# TLSR826X register map
File version: 0.1
Registers are 8-bit, access not given, no defined reset value unless marked. A register's access mark holds for its fields unless they carry their own. Offsets are from the block's base; [hi:lo] are bit positions.

## SYS — Auto-generated from section 'sys'
Base 0x00800060
0x00 RST0 32-bit — Auto-generated from rst0; aliases: RST0_16, RST_CLK0
  [31] FLD_CLK_ZB_EN, [30] FLD_CLK_ADC_EN, [29] FLD_CLK_MAC_EN, [28] FLD_CLK_MCU_EN, [27] FLD_CLK_USB_PHY_EN, [26] FLD_CLK_USB_EN, [25] FLD_CLK_I2C_EN, [24] FLD_CLK_SPI_EN, [23] FLD_RST_RSV, [22] FLD_RST_SOFT_MCIC, [21] FLD_RST_MCIC, [20] FLD_RST_SOFT_MCU, [19] FLD_RST_ADC, [18] FLD_RST_DFIFO, [17] FLD_RST_AUD, [16] FLD_RST_SBC, [15] FLD_RST_SWR_S, [14] FLD_RST_SWR_M, [13] FLD_RST_AES, [12] FLD_RST_PWM, [11] FLD_RST_UART, [10] FLD_RST_DMA, [9] FLD_RST_ALGM, [8] FLD_RST_GPIO, [7] FLD_RST_BB, [7] FLD_RST_ZB, [6] FLD_RST_AIF, [5] FLD_RST_MAC, [4] FLD_RST_MCU, [3] FLD_RST_USB_PHY, [2] FLD_RST_USB, [1] FLD_RST_I2C, [0] FLD_RST_SPI
0x01 RST1 — Auto-generated from rst1
0x02 RST2 — Auto-generated from rst2
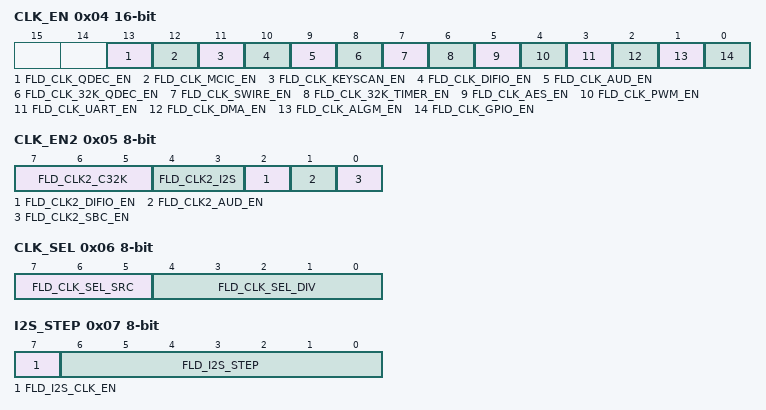
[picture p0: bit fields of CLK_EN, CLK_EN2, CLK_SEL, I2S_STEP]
0x04 CLK_EN 16-bit — Auto-generated from clk_en; aliases: CLK_EN1
  [13] FLD_CLK_QDEC_EN, [12] FLD_CLK_MCIC_EN, [11] FLD_CLK_KEYSCAN_EN, [10] FLD_CLK_DIFIO_EN, [9] FLD_CLK_AUD_EN, [8] FLD_CLK_32K_QDEC_EN, [7] FLD_CLK_SWIRE_EN, [6] FLD_CLK_32K_TIMER_EN, [5] FLD_CLK_AES_EN, [4] FLD_CLK_PWM_EN, [3] FLD_CLK_UART_EN, [2] FLD_CLK_DMA_EN, [1] FLD_CLK_ALGM_EN, [0] FLD_CLK_GPIO_EN
0x05 CLK_EN2 — Auto-generated from clk_en2
  [7:5] FLD_CLK2_C32K, [4:3] FLD_CLK2_I2S, [2] FLD_CLK2_DIFIO_EN, [1] FLD_CLK2_AUD_EN, [0] FLD_CLK2_SBC_EN
0x06 CLK_SEL — Auto-generated from clk_sel
  [7:5] FLD_CLK_SEL_SRC, [4:0] FLD_CLK_SEL_DIV
0x07 I2S_STEP — Auto-generated from i2s_step
  [7] FLD_I2S_CLK_EN, [6:0] FLD_I2S_STEP
0x08 I2S_MOD — Auto-generated from i2s_mod
0x09 ADC_STEP_L — Auto-generated from adc_step_l
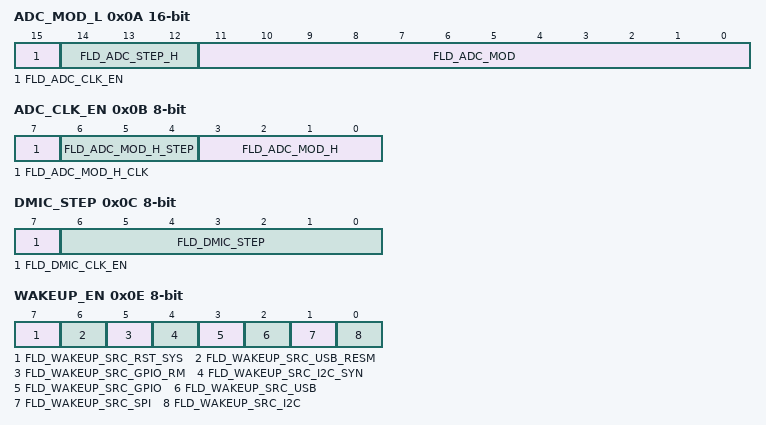
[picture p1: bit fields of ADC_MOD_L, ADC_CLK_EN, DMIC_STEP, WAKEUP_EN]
0x0A ADC_MOD_L 16-bit — Auto-generated from adc_mod_l; aliases: ADC_MOD
  [15] FLD_ADC_CLK_EN, [14:12] FLD_ADC_STEP_H, [11:0] FLD_ADC_MOD
0x0B ADC_CLK_EN — Auto-generated from adc_clk_en; aliases: ADC_MOD_H
  [7] FLD_ADC_MOD_H_CLK, [6:4] FLD_ADC_MOD_H_STEP, [3:0] FLD_ADC_MOD_H
0x0C DMIC_STEP — Auto-generated from dmic_step
  [7] FLD_DMIC_CLK_EN, [6:0] FLD_DMIC_STEP
0x0D DMIC_MOD — Auto-generated from dmic_mod
0x0E WAKEUP_EN — Auto-generated from wakeup_en
  [7] FLD_WAKEUP_SRC_RST_SYS, [6] FLD_WAKEUP_SRC_USB_RESM, [5] FLD_WAKEUP_SRC_GPIO_RM, [4] FLD_WAKEUP_SRC_I2C_SYN, [3] FLD_WAKEUP_SRC_GPIO, [2] FLD_WAKEUP_SRC_USB, [1] FLD_WAKEUP_SRC_SPI, [0] FLD_WAKEUP_SRC_I2C
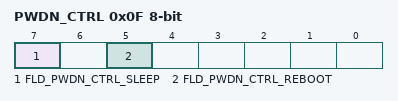
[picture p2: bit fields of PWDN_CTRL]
0x0F PWDN_CTRL — Auto-generated from pwdn_ctrl
  [7] FLD_PWDN_CTRL_SLEEP, [5] FLD_PWDN_CTRL_REBOOT
0x10 FHS_SEL — Auto-generated from fhs_sel
  [1:0] FLD_FHS_SELECT
0x11 DCDC_CLK — Auto-generated from dcdc_clk

## DEV_ID — Auto-generated from section 'dev_id'
Base 0x00800074
0x00 ID_WR_EN — Auto-generated from id_wr_en
0x04 MCU_WAKEUP_MASK 32-bit — Auto-generated from mcu_wakeup_mask
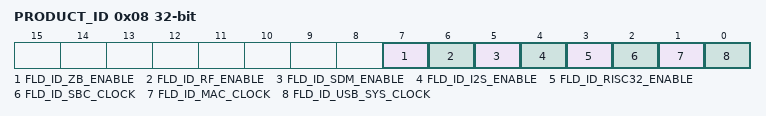
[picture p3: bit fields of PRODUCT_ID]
0x08 PRODUCT_ID 32-bit — Auto-generated from product_id; aliases: FUNC_ID
  [7] FLD_ID_ZB_ENABLE, [6] FLD_ID_RF_ENABLE, [5] FLD_ID_SDM_ENABLE, [4] FLD_ID_I2S_ENABLE, [3] FLD_ID_RISC32_ENABLE, [2] FLD_ID_SBC_CLOCK, [1] FLD_ID_MAC_CLOCK, [0] FLD_ID_USB_SYS_CLOCK
0x09 VER_ID — Auto-generated from ver_id
0x0A PROD_ID 16-bit — Auto-generated from prod_id

## MAC — Auto-generated from section 'mac'
Base 0x00800080
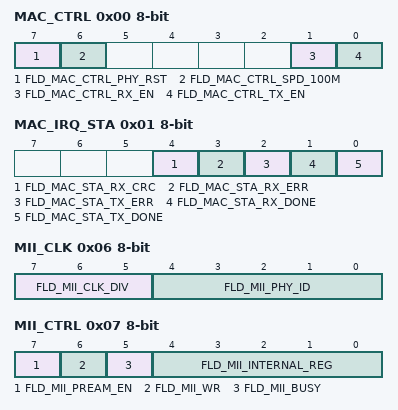
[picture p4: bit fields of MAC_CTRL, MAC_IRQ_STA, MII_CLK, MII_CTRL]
0x00 MAC_CTRL — Auto-generated from mac_ctrl
  [7] FLD_MAC_CTRL_PHY_RST, [6] FLD_MAC_CTRL_SPD_100M, [1] FLD_MAC_CTRL_RX_EN, [0] FLD_MAC_CTRL_TX_EN
0x01 MAC_IRQ_STA — Auto-generated from mac_irq_sta
  [4] FLD_MAC_STA_RX_CRC, [3] FLD_MAC_STA_RX_ERR, [2] FLD_MAC_STA_TX_ERR, [1] FLD_MAC_STA_RX_DONE, [0] FLD_MAC_STA_TX_DONE
0x02 MII_TX_DATA 16-bit — Auto-generated from mii_tx_data
0x04 MII_RX_DATA 16-bit — Auto-generated from mii_rx_data
0x06 MII_CLK — Auto-generated from mii_clk
  [7:5] FLD_MII_CLK_DIV, [4:0] FLD_MII_PHY_ID
0x07 MII_CTRL — Auto-generated from mii_ctrl
  [7] FLD_MII_PREAM_EN, [6] FLD_MII_WR, [5] FLD_MII_BUSY, [4:0] FLD_MII_INTERNAL_REG
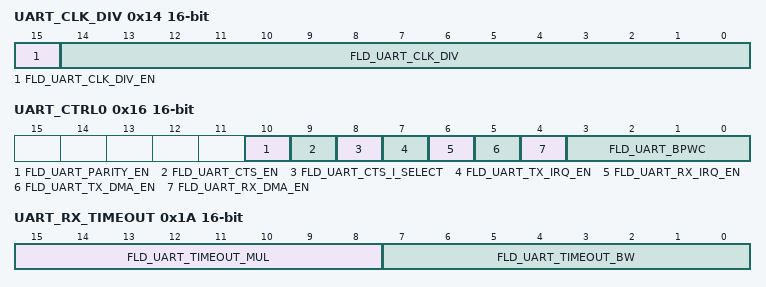
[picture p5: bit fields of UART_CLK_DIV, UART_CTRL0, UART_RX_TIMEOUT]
0x14 UART_CLK_DIV 16-bit — Auto-generated from uart_clk_div
  [15] FLD_UART_CLK_DIV_EN, [14:0] FLD_UART_CLK_DIV
0x16 UART_CTRL0 16-bit — Auto-generated from uart_ctrl0
  [10] FLD_UART_PARITY_EN, [9] FLD_UART_CTS_EN, [8] FLD_UART_CTS_I_SELECT, [7] FLD_UART_TX_IRQ_EN, [6] FLD_UART_RX_IRQ_EN, [5] FLD_UART_TX_DMA_EN, [4] FLD_UART_RX_DMA_EN, [3:0] FLD_UART_BPWC
0x18 UART_CTRL1 16-bit — Auto-generated from uart_ctrl1
0x1A UART_RX_TIMEOUT 16-bit — Auto-generated from uart_rx_timeout
  [15:8] FLD_UART_TIMEOUT_MUL, [7:0] FLD_UART_TIMEOUT_BW
